# D1H register map
Vendor: Allwinner; File version: 1.0
Registers are 32-bit, read-write, reset 0x0 unless marked. A register's access mark holds for its fields unless they carry their own. Offsets are from the block's base; [hi:lo] are bit positions; {n}, {i} and the like mark numbered series; 'fields as' and 'values as' point back to an identical list; <NAME> marks a mode.

## I2S_PCM[{n}] — I2S/PCM
Base 0x02032000; array of 3, step 0x1000
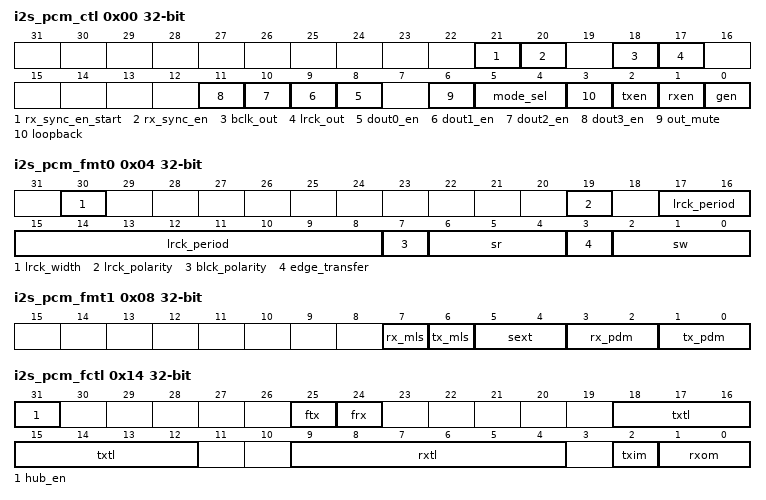
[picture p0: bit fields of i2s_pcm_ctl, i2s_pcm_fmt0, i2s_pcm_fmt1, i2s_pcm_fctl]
0x00 i2s_pcm_ctl — I2S/PCM Control Register
  [21] rx_sync_en_start — RX Synchronize Enable Start
    0=DISABLE; 1=ENABLE
  [20] rx_sync_en — RX Synchronize Enable
    0=DISABLE; 1=ENABLE
  [18] bclk_out — Bit Clock Direction Select
    0=INPUT; 1=OUTPUT
  [17] lrck_out — LRCK Direction Select
    0=INPUT; 1=OUTPUT
  [n+8] dout{n}_en (n=0..3) — Data{n} Output Enable
    0=DISABLE (Disabled, Hi-Z State); 1=ENABLE (Enabled)
  [6] out_mute — Data Output Mute Enable
    0=NORMAL; 1=ZERO
  [5:4] mode_sel — Mode Selection
    0=PCM (PCM Mode (offset 0: Long Frame, offset 1: Short Frame)); 1=LEFT (Left-justified Mode (offset 0: LJ Mode, offset 1: I2S Mode)); 2=RIGHT (Right-justified Mode)
  [3] loopback — Loopback Test
    0=NORMAL; 1=TEST
  [2] txen — Transmitter Block Enable
    0=DISABLE; 1=ENABLE
  [1] rxen — Receiver Block Enable
    0=DISABLE; 1=ENABLE
  [0] gen — Global Enable
    0=DISABLE; 1=ENABLE
0x04 i2s_pcm_fmt0 — I2S/PCM Format Register 0
  [30] lrck_width — LRCK Width (only applies to the PCM mode)
    0=SHORT (LRCK = 1 BCLK Width); 1=LONG (LRCK = 2 BCLK Width)
  [19] lrck_polarity
    0=LOW (I2S/Left-justified/Right-justified: Left-channel when LRCK is low . PCM: LRCK asserted at negative edge.); 1=HIGH (I2S/LeftJustified/Right-justified: Left-channel when LRCK is high . PCM: LRCK asserted at positive edge.)
  [17:8] lrck_period — Number of BCLKs per channel of the sample frame. This value is interpreted as follows: . PCM mode: Number of BCLKs within (Left + Right) channel width. . I2S/Left-justified/Right-justified: Number of BCLKs within each channel width (Left or Right) . Period = N + 1 e.g. N = 7: 8 BCLKs width
  [7] blck_polarity — BCLK Polarity
    0=NORMAL (DOUT drives data at negative edge); 1=INVERT (DOUT drives data at positive edge)
  [6:4] sr — Sample Resolution
    1=BITS_8 (8-bit); 2=BITS_12 (12-bit); 3=BITS_16 (16-bit); 4=BITS_20 (20-bit); 5=BITS_24 (24-bit); 6=BITS_28 (28-bit); 7=BITS_32 (32-bit)
  [3] edge_transfer
    0=ALTERNATE (DOUT drives data and DIN sample data at alternate BCLK edge); 1=SAME (DOUT drives data and DIN sample data at same BCLK edge)
  [2:0] sw — Slot Width Select
    values as sr
0x08 i2s_pcm_fmt1 — I2S/PCM Format Register 1
  [7] rx_mls — Rx MSB/LSB First Select
    0=MSB; 1=LSB
  [6] tx_mls — Tx MSB/LSB First Select
    0=MSB; 1=LSB
  [5:4] sext — Sign Extended in Slot (Sample Resolution < Slot Width)
    0=ZERO (Zeros or audio gain padding at LSB position); 1=SIGN (Sign extension at MSB position); 3=TRANSFER0 (Transfer 0 after each sample in each slot)
  [3:2] rx_pdm — Rx PCM Data Mode
    0=LINEAR (Linear PCM); 2=U_LAW (8-bit u-law); 3=A_LAW (8-bit A-law)
  [1:0] tx_pdm — Tx PCM Data Mode
    values as rx_pdm
0x0C i2s_pcm_ista — I2S/PCM Interrupt Status Register
  [all] fields
    0=NO_PENDING; 1=PENDING
  [6] txu_int — TXFIFO Underrun Pending Interrupt
  [6] rxu_int — RXFIFO Underrun Pending Interrupt
  [5] txo_int — TXFIFO Overrun Pending Interrupt
  [5] rxo_int — RXFIFO Overrun Pending Interrupt
  [4] txe_int — TXFIFO Empty Pending Interrupt
  [4] rxa_int — RXFIFO Data Available Pending Interrupt
0x10 i2s_pcm_rxfifo
  [31:0] rx_data — RX Sample . The host can get one sample by reading this register. The left channel sample data is first and then the right channel sample.
0x14 i2s_pcm_fctl — I2S/PCM FIFO Control Register
  [31] hub_en — Audio Hub Enable
  [25] ftx — Flush TXFIFO
    0=SELF_CLEAR; 1=FLUSH
  [24] frx — Flush RXFIFO
    0=SELF_CLEAR; 1=FLUSH
  [18:12] txtl — TXFIFO Empty Trigger Level . Interrupt and DMA request trigger level for TXFIFO normal condition. . Trigger Level = TXTL
  [9:4] rxtl — RXFIFO Empty Trigger Level . Interrupt and DMA request trigger level for RXFIFO normal condition. . Trigger Level = RXTL + 1
  [2] txim — TXFIFO Input Mode . Example for 20-bit transmitted audio sample: . Mode 0: TXFIFO[31:0] = {APB_WDATA[31:12], 12’h0} . Mode 1: TXFIFO[31:0] = {APB_WDATA[19:0], 12’h0}
    0=MODE0 (Valid data at the MSB of TXFIFO register); 1=MODE1 (Valid data at the LSB of TXFIFO register)
  [1:0] rxom — RXFIFO Output Mode . Example for 20-bit received audio sample: . Mode 0: APB_RDATA[31:0] = {RXFIFO[31:12], 12’h0} . Mode 1: APB_RDATA[31:0] = {12{RXFIFO[31]}, RXFIFO[31:12]} . Mode 2: APB_RDATA [31:0] = {RXFIFO[31:16], 16’h0} . Mode 3: APB_RDATA[31:0] = {16{RXFIFO[31], RXFIFO[31:16]}
    0=MODE0 (Expanding ‘0’ at LSB of RXFIFO register); 1=MODE1 (Expanding received sample sign bit at MSB of RXFIFO register); 2=MODE2 (Truncating received samples at high half-word of RXFIFO register and low half-word of RXFIFO register is filled by ‘0’); 3=MODE3 (Truncating received samples at low half-word of RXFIFO register and high half-word of RXFIFO register is expanded by its sign bit)
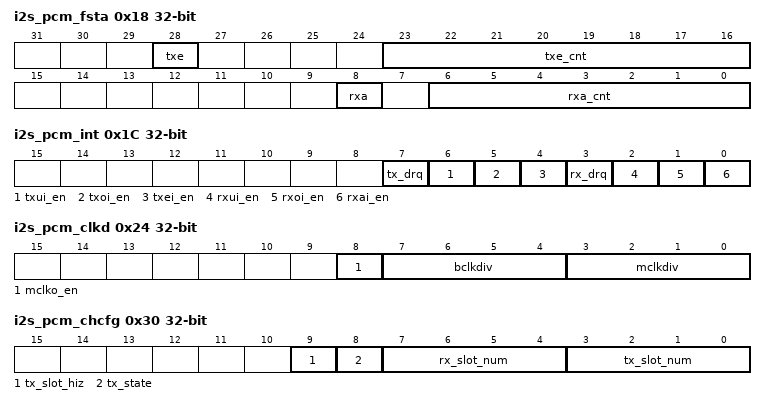
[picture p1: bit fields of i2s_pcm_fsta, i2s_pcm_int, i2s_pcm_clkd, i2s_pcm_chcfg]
0x18 i2s_pcm_fsta — I2S/PCM FIFO Status Register
  [28] txe ro — TXFIFO Empty
    0=NOT_EMPTY (No room for new sample in TXFIFO); 1=EMPTY (More than one sample in RXFIFO (>= 1 Word))
  [23:16] txe_cnt ro — TXFIFO Empty space word counter
  [8] rxa ro — RXFIFO Available
    0=NO_AVAILABLE (No Available data in RXFIFO); 1=AVAILABLE (More than one sample in RXFIFO (<= 1 Word))
  [6:0] rxa_cnt ro — RXFIFO Available sample word counter
0x1C i2s_pcm_int — I2S/PCM DMA and Interrupt Control Register
  [all] fields
    0=DISABLE (Disabled); 1=ENABLE (Enabled)
  [7] tx_drq — TXFIFO Empty DRQ Enable
  [6] txui_en — TXFIFO Underrun Interrupt Enable
  [5] txoi_en — TXFIFO Overrun Interrupt Enable
  [4] txei_en — TXFIFO Empty Interrupt Enable
  [3] rx_drq — RXFIFO Data Available DRQ Enable
  [2] rxui_en — RXFIFO Underrun Interrupt Enable
  [1] rxoi_en — RXFIFO Overrun Interrupt Enable
  [0] rxai_en — RXFIFO Data Available Interrupt Enable
0x20 i2s_pcm_txfifo
  [31:0] txdata — TX Sample . Transmitting left, right channel sample data should be written to this register one by one. The left channel sample data is first and then the right channel sample.
0x24 i2s_pcm_clkd — I2S/PCM Clock Divide Register
  [8] mclko_en — MCLK Output Enable . Note: Whether in slave or master mode, when this bit is set to ‘1’, MCLK should be output.
    0=DISABLE (Disable MCLK Output); 1=ENABLE (Enable MCLK Output)
  [7:4] bclkdiv — BCLK Divide ratio from PLL_AUDIO
    1=DIV_1 (Divide by 1); 2=DIV_2 (Divide by 2); 3=DIV_4 (Divide by 4); 4=DIV_6 (Divide by 6); 5=DIV_8 (Divide by 8); 6=DIV_12 (Divide by 12); 7=DIV_16 (Divide by 16); 8=DIV_24 (Divide by 24); 9=DIV_32 (Divide by 32); 10=DIV_48 (Divide by 48); 11=DIV_64 (Divide by 64); 12=DIV_96 (Divide by 96); 13=DIV_128 (Divide by 128); 14=DIV_176 (Divide by 176); 15=DIV_192 (Divide by 192)
  [3:0] mclkdiv — MCLK Divide ratio from PLL_AUDIO
    values as bclkdiv
0x28 i2s_pcm_txcnt — I2S/PCM TX Sample Counter Register
  [31:0] tx_cnt — TX Sample Counter
0x2C i2s_pcm_rxcnt — I2S/PCM RX Sample Counter Register
  [31:0] rx_cnt — RX Sample Counter
0x30 i2s_pcm_chcfg — I2S/PCM Channel Configuration Register
  [9] tx_slot_hiz
    0=NORMAL (Normal mode for the last half-cycle of BCLK in the slot); 1=HIZ (Turn to Hi-Z state for the last half-cycle of BCLK in the slot)
  [8] tx_state
    0=ZERO (Transfer level 0 in non-transferring slot); 1=HIZ (Turn to Hi-Z State (TDM) in non-transferring slot)
  [7:4] rx_slot_num — RX Channel/Slot number between CPU/DMA and RXFIFO . Channel or slot = N + 1
  [3:0] tx_slot_num — TX Channel/Slot number between CPU/DMA and RXFIFO . Channel or slot = N + 1
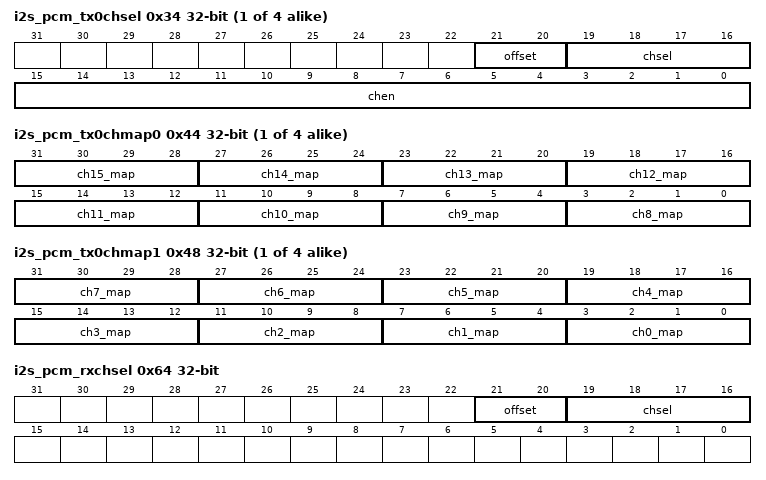
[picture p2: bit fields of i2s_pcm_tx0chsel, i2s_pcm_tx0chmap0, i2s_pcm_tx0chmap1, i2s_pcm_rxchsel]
{0x34+4i} i2s_pcm_tx{i}chsel (i=0..3) — I2S/PCM TX{i} Channel Select Register
  [21:20] offset — TX Offset Tune (TX Data offset to LRCK) . 0: No offset . N: Data is offset by N BCLKs to LRCK
  [19:16] chsel — TX Channel (Slot) number select for each output . Num channels = N + 1
  [15:0] chen — TX Channel (Slot Enable) . The bit[15:0] refer to Slot [15:0]. When one or more slots are disabled, the affected slots are set to the disable state.
{0x44+8i} i2s_pcm_tx{i}chmap0 (i=0..3) — I2S/PCM TX{i} Channel Mapping Register0
  [4n-29:4n-32] ch{n}_map (n=8..15) — Channel {n} mapping . 0000: The first sample ... . 1111: The sixteenth sample
{0x48+8i} i2s_pcm_tx{i}chmap1 (i=0..3) — I2S/PCM TX{i} Channel Mapping Register1
  [4n+3:4n] ch{n}_map (n=0..7) — Channel {n} mapping . 0000: The first sample ... . 1111: The sixteenth sample
0x64 i2s_pcm_rxchsel — I2S/PCM RX Channel Select Register
  [21:20] offset — RX Offset Tune (RX Data offset to LRCK) . 0: No offset . N: Data is offset by N BCLKs to LRCK
  [19:16] chsel — RX Channel (Slot) number select for each output . Num channels = N + 1
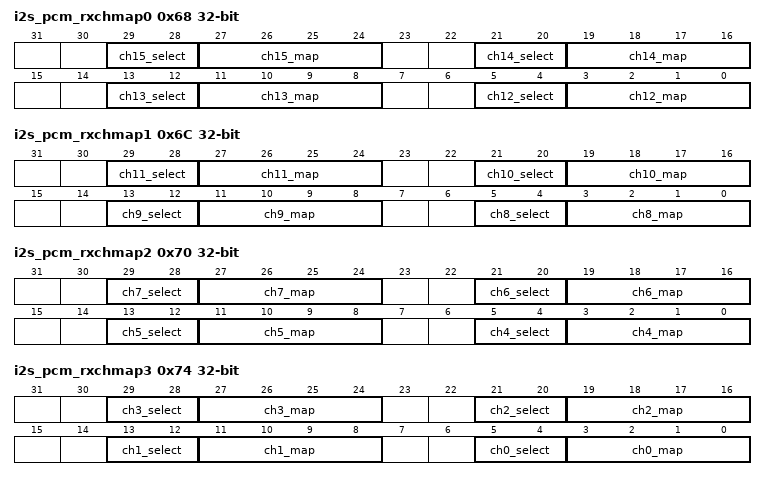
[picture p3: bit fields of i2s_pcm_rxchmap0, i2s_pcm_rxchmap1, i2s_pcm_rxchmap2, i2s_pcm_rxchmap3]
0x68 i2s_pcm_rxchmap0 — I2S/PCM RX Channel Mapping Register0
  [8n-91:8n-92] ch{n}_select (n=12..15) — RX Channel {n} Select
    {v}=SDI{v} (v=0..3)
  [8n-93:8n-96] ch{n}_map (n=12..15) — RX Channel {n} mapping . 0000: The first sample ... . 1111: The sixteenth sample
0x6C i2s_pcm_rxchmap1 — I2S/PCM RX Channel Mapping Register1
  [8n-59:8n-60] ch{n}_select (n=8..11) — RX Channel {n} Select
    {v}=SDI{v} (v=0..3)
  [8n-61:8n-64] ch{n}_map (n=8..11) — RX Channel {n} mapping . 0000: The first sample ... . 1111: The sixteenth sample
0x70 i2s_pcm_rxchmap2 — I2S/PCM RX Channel Mapping Register2
  [8n-27:8n-28] ch{n}_select (n=4..7) — RX Channel {n} Select
    {v}=SDI{v} (v=0..3)
  [8n-29:8n-32] ch{n}_map (n=4..7) — RX Channel {n} mapping . 0000: The first sample ... . 1111: The sixteenth sample
0x74 i2s_pcm_rxchmap3 — I2S/PCM RX Channel Mapping Register3
  [8n+5:8n+4] ch{n}_select (n=0..3) — RX Channel {n} Select
    {v}=SDI{v} (v=0..3)
  [8n+3:8n] ch{n}_map (n=0..3) — RX Channel {n} mapping . 0000: The first sample ... . 1111: The sixteenth sample
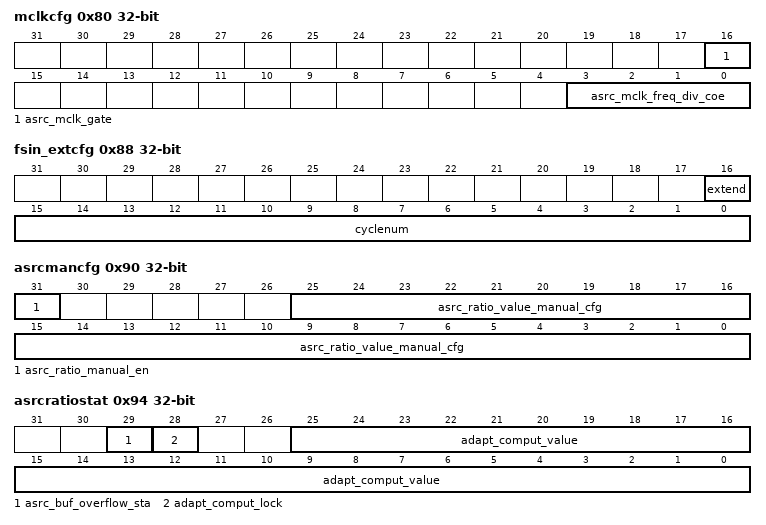
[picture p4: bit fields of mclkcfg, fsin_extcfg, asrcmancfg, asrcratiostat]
0x80 mclkcfg — ASRC MCLK Configuration Register
  [16] asrc_mclk_gate — ASRC Clock Gate Enable Control
    0=DISABLE; 1=ENABLE
  [3:0] asrc_mclk_freq_div_coe — Frequency Division Coefficient
    0=R_ESERVED (Reserved. No output.); 1=DIV1 (1/1); 2=DIV2 (1/2); 3=DIV4 (1/4); 4=DIV6 (1/6); 5=DIV8 (1/8); 6=DIV12 (1/12); 7=DIV16 (1/16); 8=DIV24 (1/24); 9=DIV32 (1/32); 10=DIV48 (1/48); 11=DIV64 (1/64); 12=DIV96 (1/96); 13=DIV128 (1/128); 14=DIV176 (1/176); 15=DIV192 (1/192)
0x84 fsout_cfg — ASRC Out Sample Rate Configuration Register
  [20] fsout_gate — fsout Clock Gate Enable Control
    0=DISABLE; 1=ENABLE
0x88 fsin_extcfg — ASRC Input Sample Pulse Extend Configuration Register
  [16] extend — Extend the bit when using ASRC.
    0=DISABLE; 1=ENABLE
  [15:0] cyclenum — The Cycle Number of Pulse Extend. . The cycle is BCLK and is at least 1.
0x8C asrcen — ASRC Enable Register
  [31] asrc_fn — ASRC Function Enable
    0=DISABLE; 1=ENABLE
0x90 asrcmancfg — ASRC Manual Ratio Configuration Register
  [31] asrc_ratio_manual_en — Manual Configuration of ASRC Ratio Enable
    0=DISABLE; 1=ENABLE
  [25:0] asrc_ratio_value_manual_cfg — ASRD Ration Value Manual Configure
0x94 asrcratiostat — ASRC Status Register
  [29] asrc_buf_overflow_sta — ASRC Receive Data Buffer Overflow State . It can control thye mute with lock.
    0=NO_OVERFLOW (Disable); 1=OVERFLOW (Enable)
  [28] adapt_comput_lock — Adaptive Ratio Computational Lock
    0=UNLOCKED (Disable); 1=LOCKED (Enable)
  [25:0] adapt_comput_value — Adaptive Ratio Computational Value
0x98 asrcfifostat — ASRC FIFO Level Status Register
  [8:0] asrc_rx_fifo_full_leval — ASRC RXFIFO Full Level . The manually-configured FIFO fill level for the ratio value of the received data.
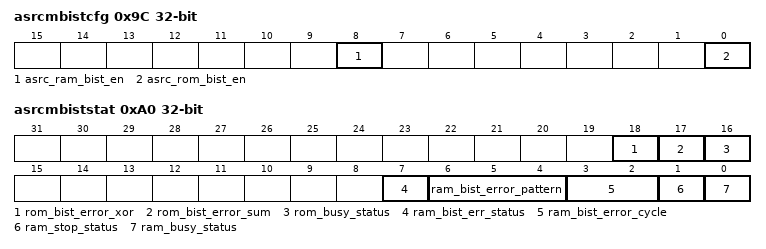
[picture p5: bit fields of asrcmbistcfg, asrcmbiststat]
0x9C asrcmbistcfg — ASRC MBIST Test Configuration Register
  [8] asrc_ram_bist_en — ASTC RAM BIST Enable
    0=DISABLE; 1=ENABLE
  [0] asrc_rom_bist_en — ASRC ROM BIST Enable
    0=DISABLE; 1=ENABLE
0xA0 asrcmbiststat — ASRC MBIST Test Status Register
  [18] rom_bist_error_xor ro
  [17] rom_bist_error_sum ro
  [16] rom_busy_status ro
    0=IDLE; 1=BUSY
  [7] ram_bist_err_status ro — RAM BIST error status
    0=NO_EFFECT; 1=ERROR
  [6:4] ram_bist_error_pattern ro
  [3:2] ram_bist_error_cycle ro
  [1] ram_stop_status ro
    0=RUNNING; 1=STOP
  [0] ram_busy_status ro
    0=IDLE; 1=BUSY
